VERSION "1"

NS_ :

BS_:

BU_:

BO_ 1902 Lanes_Host_Header: 1 Vector__XXX
 SG_ Is_Construction_Area : 0|1@1+ (1,0) [0|1] "bool" Vector__XXX
 SG_ Reserved : 1|7@1+ (1,0) [0|0] "NA" Vector__XXX

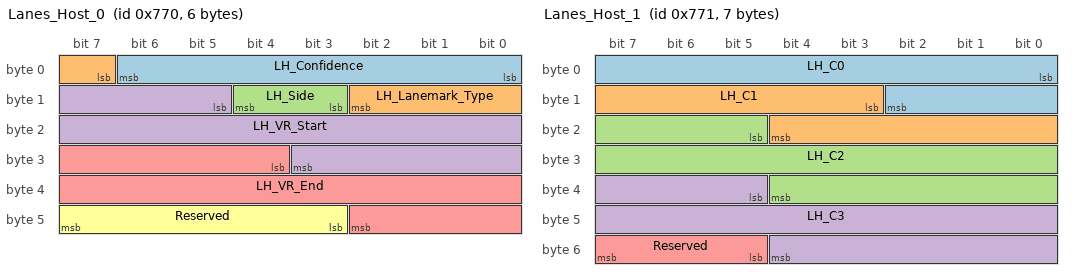
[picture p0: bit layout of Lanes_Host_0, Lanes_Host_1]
BO_ 1904 Lanes_Host_0: 6 Vector__XXX
 SG_ LH_Confidence : 0|7@1+ (0.01,0) [0|1] "NA" Vector__XXX
 SG_ LH_Lanemark_Type : 7|4@1+ (1,0) [0|6] "ENUM" Vector__XXX
 SG_ LH_Side : 11|2@1+ (1,0) [0|2] "ENUM" Vector__XXX
 SG_ LH_VR_Start : 13|15@1+ (0.01,0) [0|200] "m" Vector__XXX
 SG_ LH_VR_End : 28|15@1+ (0.01,0) [0|200] "m" Vector__XXX
 SG_ Reserved : 43|5@1+ (1,0) [0|0] "NA" Vector__XXX

BO_ 1905 Lanes_Host_1: 7 Vector__XXX
 SG_ LH_C0 : 0|11@1+ (0.01,-10) [-10|10] "meter" Vector__XXX
 SG_ LH_C1 : 11|10@1+ (0.000977,-0.357) [-0.357|0.357] "rad" Vector__XXX
 SG_ LH_C2 : 21|16@1+ (9.77E-007,-0.032) [-0.032|0.032] "1/m" Vector__XXX
 SG_ LH_C3 : 37|16@1+ (3.73E-009,-0.000122) [-0.000122|0.000122] "1/m2" Vector__XXX
 SG_ Reserved : 53|3@1+ (1,0) [0|0] "NA" Vector__XXX

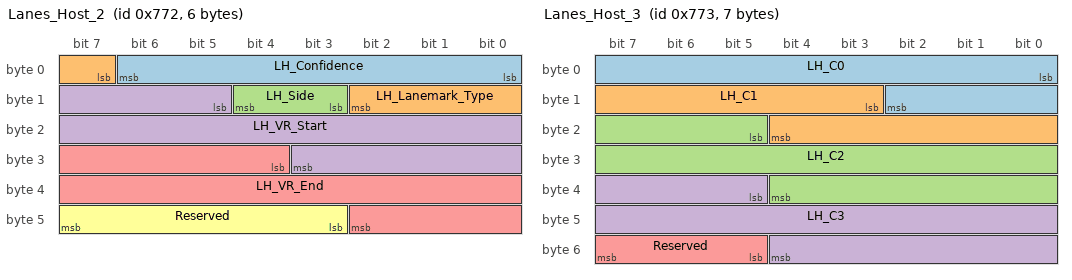
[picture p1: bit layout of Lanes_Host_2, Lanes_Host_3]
BO_ 1906 Lanes_Host_2: 6 Vector__XXX
 SG_ LH_Confidence : 0|7@1+ (0.01,0) [0|1] "NA" Vector__XXX
 SG_ LH_Lanemark_Type : 7|4@1+ (1,0) [0|6] "ENUM" Vector__XXX
 SG_ LH_Side : 11|2@1+ (1,0) [0|2] "ENUM" Vector__XXX
 SG_ LH_VR_Start : 13|15@1+ (0.01,0) [0|200] "m" Vector__XXX
 SG_ LH_VR_End : 28|15@1+ (0.01,0) [0|200] "m" Vector__XXX
 SG_ Reserved : 43|5@1+ (1,0) [0|0] "NA" Vector__XXX

BO_ 1907 Lanes_Host_3: 7 Vector__XXX
 SG_ LH_C0 : 0|11@1+ (0.01,-10) [-10|10] "meter" Vector__XXX
 SG_ LH_C1 : 11|10@1+ (0.000977,-0.357) [-0.357|0.357] "rad" Vector__XXX
 SG_ LH_C2 : 21|16@1+ (9.77E-007,-0.032) [-0.032|0.032] "1/m" Vector__XXX
 SG_ LH_C3 : 37|16@1+ (3.73E-009,-0.000122) [-0.000122|0.000122] "1/m2" Vector__XXX
 SG_ Reserved : 53|3@1+ (1,0) [0|0] "NA" Vector__XXX

CM_ SG_ 1902 Is_Construction_Area "True if this is a construction area scene. ";
CM_ SG_ 1904 LH_Confidence "Confidence of lane mark ";
CM_ SG_ 1904 LH_Lanemark_Type "Lane Mark Type Classification (first segment only)";
CM_ SG_ 1904 LH_Side "Lane mark side";
CM_ SG_ 1904 LH_VR_Start "Start of longitudinal view range of lane mark";
CM_ SG_ 1904 LH_VR_End "End of longitudinal view range of lane mark";
CM_ SG_ 1905 LH_C0 "Ci is coefficient corresponding to variable with power of 'i'";
CM_ SG_ 1905 LH_C1 "Ci is coefficient corresponding to variable with power of 'i'";
CM_ SG_ 1905 LH_C2 "Ci is coefficient corresponding to variable with power of 'i'";
CM_ SG_ 1905 LH_C3 "Ci is coefficient corresponding to variable with power of 'i'";
CM_ SG_ 1906 LH_Confidence "Confidence of lane mark ";
CM_ SG_ 1906 LH_Lanemark_Type "Lane Mark Type Classification (first segment only)";
CM_ SG_ 1906 LH_Side "Lane mark side";
CM_ SG_ 1906 LH_VR_Start "Start of longitudinal view range of lane mark";
CM_ SG_ 1906 LH_VR_End "End of longitudinal view range of lane mark";
CM_ SG_ 1907 LH_C0 "Ci is coefficient corresponding to variable with power of 'i'";
CM_ SG_ 1907 LH_C1 "Ci is coefficient corresponding to variable with power of 'i'";
CM_ SG_ 1907 LH_C2 "Ci is coefficient corresponding to variable with power of 'i'";
CM_ SG_ 1907 LH_C3 "Ci is coefficient corresponding to variable with power of 'i'";
BA_DEF_  "BusType" STRING ;
BA_DEF_DEF_  "BusType" "CAN";
VAL_ 1902 Is_Construction_Area 1 "TRUE" 0 "FALSE" ;
VAL_ 1904 LH_Lanemark_Type 6 "HOV_LANE" 5 "DECELERATION" 4 "BOTTS" 3 "DLM" 2 "DASHED" 1 "SOLID" 0 "UNDECIDED" ;
VAL_ 1904 LH_Side 2 "RIGHT" 1 "LEFT" 0 "UNKNOWN" ;
VAL_ 1906 LH_Lanemark_Type 6 "HOV_LANE" 5 "DECELERATION" 4 "BOTTS" 3 "DLM" 2 "DASHED" 1 "SOLID" 0 "UNDECIDED" ;
VAL_ 1906 LH_Side 2 "RIGHT" 1 "LEFT" 0 "UNKNOWN" ;
